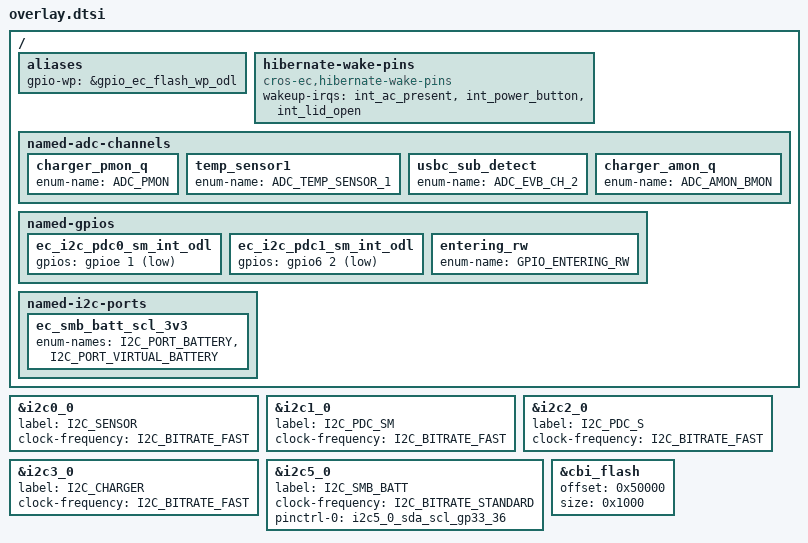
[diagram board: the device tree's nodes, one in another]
/* Copyright 2023 The ChromiumOS Authors
 * Use of this source code is governed by a BSD-style license that can be
 * found in the LICENSE file.
 *
 */

/ {
	aliases {
		gpio-wp = &gpio_ec_flash_wp_odl;
	};

	hibernate-wake-pins {
		compatible = "cros-ec,hibernate-wake-pins";
		wakeup-irqs = <
			&int_ac_present
			&int_power_button
			&int_lid_open
		>;
	};

	named-adc-channels {
		charger_pmon_q {
			enum-name = "ADC_PMON";
		};

		temp_sensor1 {
			enum-name = "ADC_TEMP_SENSOR_1";
		};

		usbc_sub_detect {
			/* TODO: update its name */
			enum-name = "ADC_EVB_CH_2";
		};

		charger_amon_q {
			enum-name = "ADC_AMON_BMON";
		};
	};

	named-gpios {
		ec_i2c_pdc0_sm_int_odl {
			gpios = <&gpioe 1 (GPIO_INPUT | GPIO_ACTIVE_LOW)>;
		};

		ec_i2c_pdc1_sm_int_odl {
			gpios = <&gpio6 2 (GPIO_INPUT | GPIO_ACTIVE_LOW)>;
		};

		entering_rw {
			enum-name = "GPIO_ENTERING_RW";
		};
	};

	named-i2c-ports {
		ec_smb_batt_scl_3v3 {
			enum-names = "I2C_PORT_BATTERY", "I2C_PORT_VIRTUAL_BATTERY";
		};
	};
};

&i2c0_0 {
	label = "I2C_SENSOR";
	clock-frequency = <I2C_BITRATE_FAST>;
};

&i2c1_0 {
	label = "I2C_PDC_SM";
	clock-frequency = <I2C_BITRATE_FAST>;
};

&i2c2_0 {
	label = "I2C_PDC_S";
	clock-frequency = <I2C_BITRATE_FAST>;
};

&i2c3_0 {
	label = "I2C_CHARGER";
	clock-frequency = <I2C_BITRATE_FAST>;
};

&i2c5_0 {
	label = "I2C_SMB_BATT";
	clock-frequency = <I2C_BITRATE_STANDARD>;
	/* Upstream zephyr uses an irregular name here */
	pinctrl-0 = <&i2c5_0_sda_scl_gp33_36>;
};

&cbi_flash {
	/*
	 * CBI section size is 0x1000 bytes, the CBI portion lies at the end of
	 * EC_RO section. EC_RO section ends at 0x50000 byte which is the offset
	 */
	offset = <0x50000>;
	size = <0x1000>;
};
